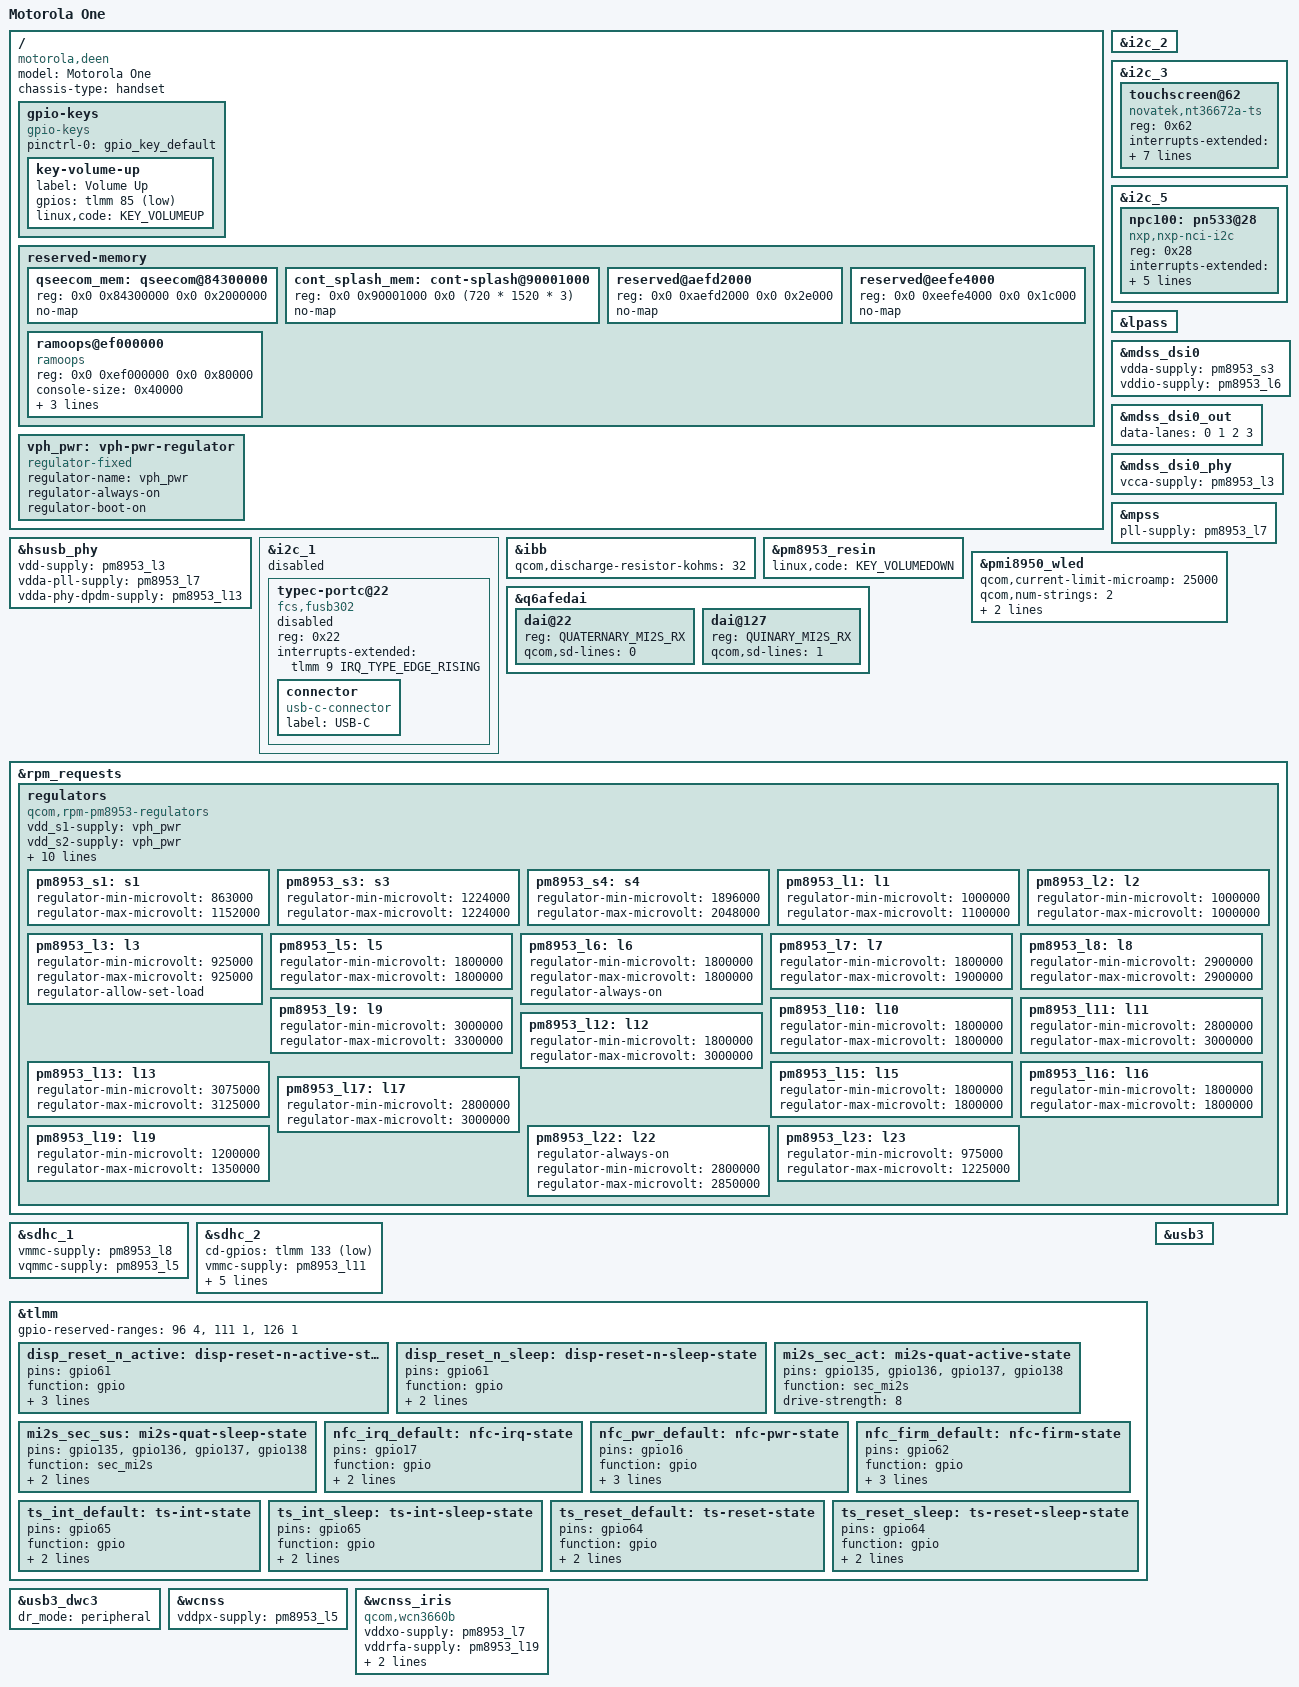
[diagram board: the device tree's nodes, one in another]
// SPDX-License-Identifier: (GPL-2.0+ OR BSD-3-Clause)
/*
 * Copyright (c) 2026 Adam Skladowski <a39skl@gmail.com>
 */

/dts-v1/;

#include "msm8953.dtsi"
#include "pm8953.dtsi"
#include "pmi8950.dtsi"

/delete-node/ &cont_splash_mem;
/delete-node/ &qseecom_mem;

/ {
	model = "Motorola One";
	compatible = "motorola,deen", "qcom,msm8953";
	chassis-type = "handset";

	gpio-keys {
		compatible = "gpio-keys";

		pinctrl-0 = <&gpio_key_default>;
		pinctrl-names = "default";

		key-volume-up {
			label = "Volume Up";
			gpios = <&tlmm 85 GPIO_ACTIVE_LOW>;
			linux,code = <KEY_VOLUMEUP>;
		};
	};

	reserved-memory {
		qseecom_mem: qseecom@84300000 {
			reg = <0x0 0x84300000 0x0 0x2000000>;
			no-map;
		};

		cont_splash_mem: cont-splash@90001000 {
			reg = <0x0 0x90001000 0x0 (720 * 1520 * 3)>;
			no-map;
		};

		reserved@aefd2000 {
			reg = <0x0 0xaefd2000 0x0 0x2e000>;
			no-map;
		};

		reserved@eefe4000 {
			reg = <0x0 0xeefe4000 0x0 0x1c000>;
			no-map;
		};

		ramoops@ef000000 {
			compatible = "ramoops";
			reg = <0x0 0xef000000 0x0 0x80000>;
			console-size = <0x40000>;
			ftrace-size = <0>;
			record-size = <0x3f800>;
			pmsg-size = <0x800>;
		};
	};

	vph_pwr: vph-pwr-regulator {
		compatible = "regulator-fixed";
		regulator-name = "vph_pwr";
		regulator-always-on;
		regulator-boot-on;
	};
};

&hsusb_phy {
	vdd-supply = <&pm8953_l3>;
	vdda-pll-supply = <&pm8953_l7>;
	vdda-phy-dpdm-supply = <&pm8953_l13>;

	status = "okay";
};

&i2c_1 {
	status = "disabled";

	typec-portc@22 {
		compatible = "fcs,fusb302";
		reg = <0x22>;
		interrupts-extended = <&tlmm 9 IRQ_TYPE_EDGE_RISING>;

		status = "disabled";

		connector {
			compatible = "usb-c-connector";
			label = "USB-C";
		};
	};
};

&i2c_2 {
	status = "okay";
};

&i2c_3 {
	status = "okay";

	touchscreen@62 {
		compatible = "novatek,nt36672a-ts";
		reg = <0x62>;

		interrupts-extended = <&tlmm 65 IRQ_TYPE_EDGE_RISING>;
		reset-gpios = <&tlmm 64 GPIO_ACTIVE_LOW>;

		iovcc-supply = <&pm8953_l6>;

		pinctrl-0 = <&ts_reset_default &ts_int_default>;
		pinctrl-1 = <&ts_reset_sleep &ts_int_sleep>;
		pinctrl-names = "default", "sleep";

		touchscreen-size-x = <720>;
		touchscreen-size-y = <1520>;
	};
};

&i2c_5 {
	status = "okay";

	npc100: pn533@28 {
		compatible = "nxp,nxp-nci-i2c";

		reg = <0x28>;

		interrupts-extended = <&tlmm 17 IRQ_TYPE_LEVEL_HIGH>;

		enable-gpios = <&tlmm 16 GPIO_ACTIVE_HIGH>;
		firmware-gpios = <&tlmm 62 GPIO_ACTIVE_HIGH>;

		pinctrl-0 = <&nfc_firm_default &nfc_irq_default &nfc_pwr_default>;
		pinctrl-names = "default";
	};
};

&ibb {
	qcom,discharge-resistor-kohms = <32>;
};

&lpass {
	status = "okay";
};

&mdss_dsi0 {
	vdda-supply = <&pm8953_s3>;
	vddio-supply = <&pm8953_l6>;
};

&mdss_dsi0_out {
	data-lanes = <0 1 2 3>;
};

&mdss_dsi0_phy {
	vcca-supply = <&pm8953_l3>;
};

&mpss {
	pll-supply = <&pm8953_l7>;

	status = "okay";
};

&pm8953_resin {
	linux,code = <KEY_VOLUMEDOWN>;
	status = "okay";
};

&pmi8950_wled {
	qcom,current-limit-microamp = <25000>;
	qcom,num-strings = <2>;
	qcom,cabc;
	qcom,external-pfet;
};

&q6afedai {
	dai@22 {
		reg = <QUATERNARY_MI2S_RX>;
		qcom,sd-lines = <0>;
	};

	dai@127 {
		reg = <QUINARY_MI2S_RX>;
		qcom,sd-lines = <1>;
	};
};

&rpm_requests {
	regulators {
		compatible = "qcom,rpm-pm8953-regulators";
		vdd_s1-supply = <&vph_pwr>;
		vdd_s2-supply = <&vph_pwr>;
		vdd_s3-supply = <&vph_pwr>;
		vdd_s4-supply = <&vph_pwr>;
		vdd_s5-supply = <&vph_pwr>;
		vdd_s6-supply = <&vph_pwr>;
		vdd_s7-supply = <&vph_pwr>;
		vdd_l1-supply = <&pm8953_s3>;
		vdd_l2_l3-supply = <&pm8953_s3>;
		vdd_l4_l5_l6_l7_l16_l19-supply = <&pm8953_s4>;
		vdd_l8_l11_l12_l13_l14_l15-supply = <&vph_pwr>;
		vdd_l9_l10_l17_l18_l22-supply = <&vph_pwr>;

		pm8953_s1: s1 {
			regulator-min-microvolt = <863000>;
			regulator-max-microvolt = <1152000>;
		};

		pm8953_s3: s3 {
			regulator-min-microvolt = <1224000>;
			regulator-max-microvolt = <1224000>;
		};

		pm8953_s4: s4 {
			regulator-min-microvolt = <1896000>;
			regulator-max-microvolt = <2048000>;
		};

		pm8953_l1: l1 {
			regulator-min-microvolt = <1000000>;
			regulator-max-microvolt = <1100000>;
		};

		pm8953_l2: l2 {
			regulator-min-microvolt = <1000000>;
			regulator-max-microvolt = <1000000>;
		};

		pm8953_l3: l3 {
			regulator-min-microvolt = <925000>;
			regulator-max-microvolt = <925000>;
			regulator-allow-set-load;
		};

		pm8953_l5: l5 {
			regulator-min-microvolt = <1800000>;
			regulator-max-microvolt = <1800000>;
		};

		pm8953_l6: l6 {
			regulator-min-microvolt = <1800000>;
			regulator-max-microvolt = <1800000>;
			regulator-always-on;
		};

		pm8953_l7: l7 {
			regulator-min-microvolt = <1800000>;
			regulator-max-microvolt = <1900000>;
		};

		pm8953_l8: l8 {
			regulator-min-microvolt = <2900000>;
			regulator-max-microvolt = <2900000>;
		};

		pm8953_l9: l9 {
			regulator-min-microvolt = <3000000>;
			regulator-max-microvolt = <3300000>;
		};

		pm8953_l10: l10 {
			regulator-min-microvolt = <1800000>;
			regulator-max-microvolt = <1800000>;
		};

		pm8953_l11: l11 {
			regulator-min-microvolt = <2800000>;
			regulator-max-microvolt = <3000000>;
		};

		pm8953_l12: l12 {
			regulator-min-microvolt = <1800000>;
			regulator-max-microvolt = <3000000>;
		};

		pm8953_l13: l13 {
			regulator-min-microvolt = <3075000>;
			regulator-max-microvolt = <3125000>;
		};

		pm8953_l15: l15 {
			regulator-min-microvolt = <1800000>;
			regulator-max-microvolt = <1800000>;
		};

		pm8953_l16: l16 {
			regulator-min-microvolt = <1800000>;
			regulator-max-microvolt = <1800000>;
		};

		pm8953_l17: l17 {
			regulator-min-microvolt = <2800000>;
			regulator-max-microvolt = <3000000>;
		};

		pm8953_l19: l19 {
			regulator-min-microvolt = <1200000>;
			regulator-max-microvolt = <1350000>;
		};

		pm8953_l22: l22 {
			regulator-always-on;
			regulator-min-microvolt = <2800000>;
			regulator-max-microvolt = <2850000>;
		};

		pm8953_l23: l23 {
			regulator-min-microvolt = <975000>;
			regulator-max-microvolt = <1225000>;
		};
	};
};

&sdhc_1 {
	vmmc-supply = <&pm8953_l8>;
	vqmmc-supply = <&pm8953_l5>;

	status = "okay";
};

&sdhc_2 {
	cd-gpios = <&tlmm 133 GPIO_ACTIVE_LOW>;

	vmmc-supply = <&pm8953_l11>;
	vqmmc-supply = <&pm8953_l12>;

	pinctrl-0 = <&sdc2_clk_on &sdc2_cmd_on &sdc2_data_on &sdc2_cd_off>;
	pinctrl-1 = <&sdc2_clk_off &sdc2_cmd_off &sdc2_data_off &sdc2_cd_off>;
	pinctrl-names = "default", "sleep";

	status = "okay";
};

&tlmm {
	gpio-reserved-ranges = <96 4>, <111 1>, <126 1>;

	disp_reset_n_active: disp-reset-n-active-state {
		pins = "gpio61";
		function = "gpio";
		drive-strength = <8>;
		bias-disable;
		output-high;
	};

	disp_reset_n_sleep: disp-reset-n-sleep-state {
		pins = "gpio61";
		function = "gpio";
		drive-strength = <2>;
		bias-pull-down;
	};

	mi2s_sec_act: mi2s-quat-active-state {
		pins = "gpio135", "gpio136", "gpio137", "gpio138";
		function = "sec_mi2s";
		drive-strength = <8>;
	};

	mi2s_sec_sus: mi2s-quat-sleep-state {
		pins = "gpio135", "gpio136", "gpio137", "gpio138";
		function = "sec_mi2s";
		drive-strength = <2>;
		bias-pull-down;
	};

	nfc_irq_default: nfc-irq-state {
		pins = "gpio17";
		function = "gpio";
		bias-pull-down;
		drive-strength = <2>;
	};

	nfc_pwr_default: nfc-pwr-state {
		pins = "gpio16";
		function = "gpio";
		bias-pull-down;
		output-low;
		drive-strength = <2>;
	};

	nfc_firm_default: nfc-firm-state {
		pins = "gpio62";
		function = "gpio";
		bias-pull-down;
		output-low;
		drive-strength = <2>;
	};

	ts_int_default: ts-int-state {
		pins = "gpio65";
		function = "gpio";
		drive-strength = <8>;
		bias-pull-up;
	};

	ts_int_sleep: ts-int-sleep-state {
		pins = "gpio65";
		function = "gpio";
		drive-strength = <2>;
		bias-pull-down;
	};

	ts_reset_default: ts-reset-state {
		pins = "gpio64";
		function = "gpio";
		drive-strength = <8>;
		bias-pull-up;
	};

	ts_reset_sleep: ts-reset-sleep-state {
		pins = "gpio64";
		function = "gpio";
		drive-strength = <2>;
		bias-pull-down;
	};
};

&usb3 {
	status = "okay";
};

&usb3_dwc3 {
	dr_mode = "peripheral";
};

&wcnss {
	vddpx-supply = <&pm8953_l5>;

	status = "okay";
};

&wcnss_iris {
	compatible = "qcom,wcn3660b";

	vddxo-supply = <&pm8953_l7>;
	vddrfa-supply = <&pm8953_l19>;
	vddpa-supply = <&pm8953_l9>;
	vdddig-supply = <&pm8953_l5>;

	status = "okay";
};
